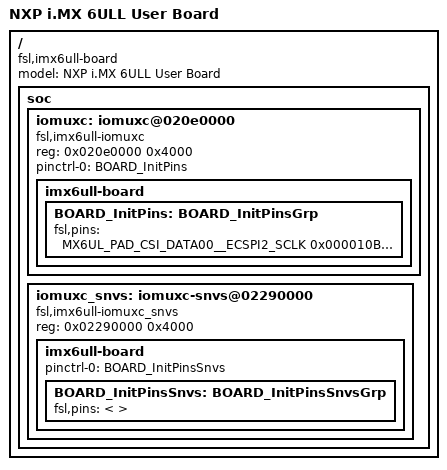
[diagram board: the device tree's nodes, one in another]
/***********************************************************************************************************************
 * This file was generated by the MCUXpresso Config Tools. Any manual edits made to this file
 * will be overwritten if the respective MCUXpresso Config Tools is used to update this file.
 **********************************************************************************************************************/

/*
 * TEXT BELOW IS USED AS SETTING FOR TOOLS *************************************
!!GlobalInfo
product: Pins v11.0
processor: MCIMX6Y2xxx05
package_id: MCIMX6Y2DVM05
mcu_data: i_mx_2_0
processor_version: 11.0.0
 * BE CAREFUL MODIFYING THIS COMMENT - IT IS YAML SETTINGS FOR TOOLS ***********
 */

/*
 * TEXT BELOW IS USED AS SETTING FOR TOOLS *************************************
BOARD_InitPins:
- options: {callFromInitBoot: 'false', coreID: ca7}
- pin_list:
  - {pin_num: B3, peripheral: uSDHC1, signal: 'usdhc_data, 0', pin_signal: SD1_DATA0}
  - {pin_num: B2, peripheral: uSDHC1, signal: 'usdhc_data, 1', pin_signal: SD1_DATA1}
  - {pin_num: A2, peripheral: uSDHC1, signal: 'usdhc_data, 3', pin_signal: SD1_DATA3}
  - {pin_num: B1, peripheral: uSDHC1, signal: 'usdhc_data, 2', pin_signal: SD1_DATA2}
  - {pin_num: C2, peripheral: uSDHC1, signal: usdhc_cmd, pin_signal: SD1_CMD}
  - {pin_num: C1, peripheral: uSDHC1, signal: usdhc_clk, pin_signal: SD1_CLK}
  - {pin_num: L14, peripheral: I2C1, signal: i2c_scl, pin_signal: GPIO1_IO02}
  - {pin_num: L17, peripheral: I2C1, signal: i2c_sda, pin_signal: GPIO1_IO03}
  - {pin_num: K13, peripheral: I2C2, signal: i2c_scl, pin_signal: GPIO1_IO00}
  - {pin_num: L15, peripheral: I2C2, signal: i2c_sda, pin_signal: GPIO1_IO01}
  - {pin_num: A9, peripheral: I2C3, signal: i2c_scl, pin_signal: LCD_DATA01}
  - {pin_num: B9, peripheral: I2C3, signal: i2c_sda, pin_signal: LCD_DATA00}
  - {pin_num: D10, peripheral: I2C4, signal: i2c_scl, pin_signal: LCD_DATA03}
  - {pin_num: E10, peripheral: I2C4, signal: i2c_sda, pin_signal: LCD_DATA02}
  - {pin_num: F5, peripheral: UART6, signal: uart_rx, pin_signal: CSI_MCLK}
  - {pin_num: E5, peripheral: UART6, signal: uart_tx, pin_signal: CSI_PIXCLK}
  - {pin_num: C13, peripheral: UART7, signal: uart_rx, pin_signal: LCD_DATA16}
  - {pin_num: B13, peripheral: UART7, signal: uart_tx, pin_signal: LCD_DATA17}
  - {pin_num: C14, peripheral: UART8, signal: uart_rx, pin_signal: LCD_DATA20}
  - {pin_num: B14, peripheral: UART8, signal: uart_tx, pin_signal: LCD_DATA21}
  - {pin_num: G13, peripheral: UART5, signal: uart_rx, pin_signal: UART5_RX_DATA}
  - {pin_num: F17, peripheral: UART5, signal: uart_tx, pin_signal: UART5_TX_DATA}
  - {pin_num: G16, peripheral: UART4, signal: uart_rx, pin_signal: UART4_RX_DATA}
  - {pin_num: G17, peripheral: UART4, signal: uart_tx, pin_signal: UART4_TX_DATA}
  - {pin_num: H17, peripheral: UART3, signal: uart_tx, pin_signal: UART3_TX_DATA}
  - {pin_num: H16, peripheral: UART3, signal: uart_rx, pin_signal: UART3_RX_DATA}
  - {pin_num: J17, peripheral: UART2, signal: uart_tx, pin_signal: UART2_TX_DATA}
  - {pin_num: J16, peripheral: UART2, signal: uart_rx, pin_signal: UART2_RX_DATA}
  - {pin_num: K16, peripheral: UART1, signal: uart_rx, pin_signal: UART1_RX_DATA}
  - {pin_num: K14, peripheral: UART1, signal: uart_tx, pin_signal: UART1_TX_DATA}
  - {pin_num: D3, peripheral: uSDHC1, signal: usdhc_cd_b, pin_signal: CSI_DATA05}
  - {pin_num: E1, peripheral: ECSPI2, signal: ecspi_miso, pin_signal: CSI_DATA03}
  - {pin_num: E2, peripheral: ECSPI2, signal: ecspi_mosi, pin_signal: CSI_DATA02}
  - {pin_num: E4, peripheral: ECSPI2, signal: ecspi_sclk, pin_signal: CSI_DATA00}
  - {pin_num: E3, peripheral: ECSPI2, signal: 'ecspi_ss, 0', pin_signal: CSI_DATA01}
  - {pin_num: B16, peripheral: ECSPI1, signal: ecspi_miso, pin_signal: LCD_DATA23}
  - {pin_num: A14, peripheral: ECSPI1, signal: ecspi_mosi, pin_signal: LCD_DATA22}
  - {pin_num: C14, peripheral: ECSPI1, signal: ecspi_sclk, pin_signal: LCD_DATA20}
 * BE CAREFUL MODIFYING THIS COMMENT - IT IS YAML SETTINGS FOR TOOLS ***********
 */

/dts-v1/;

#include "skeleton.dtsi"
#include "imx6ull-pinfunc.h"
#include "imx6ull-pinfunc-snvs.h"

/ {
    model = "NXP i.MX 6ULL User Board";
    compatible = "fsl,imx6ull-board", "fsl,imx6ull";

    soc {
        #address-cells = <1>;
        #size-cells = <1>;

        iomuxc: iomuxc@020e0000 {
            compatible = "fsl,imx6ull-iomuxc";
            reg = <0x020e0000 0x4000>;
        };

        iomuxc_snvs: iomuxc-snvs@02290000 {
            compatible = "fsl,imx6ull-iomuxc_snvs";
            reg = <0x02290000 0x4000>;
        };
    };
};

&iomuxc {
    pinctrl-names = "default";
    pinctrl-0 = <&BOARD_InitPins>;
    imx6ull-board {
        BOARD_InitPins: BOARD_InitPinsGrp {                /*!< Function assigned for the core: Cortex-A7[ca7] */
            fsl,pins = <
                MX6UL_PAD_CSI_DATA00__ECSPI2_SCLK          0x000010B0
                MX6UL_PAD_CSI_DATA01__ECSPI2_SS0           0x000010B0
                MX6UL_PAD_CSI_DATA02__ECSPI2_MOSI          0x000010B0
                MX6UL_PAD_CSI_DATA03__ECSPI2_MISO          0x000010B0
                MX6UL_PAD_CSI_DATA05__USDHC1_CD_B          0x000010B0
                MX6UL_PAD_CSI_MCLK__UART6_DCE_TX           0x000010B0
                MX6UL_PAD_CSI_PIXCLK__UART6_DCE_RX         0x000010B0
                MX6UL_PAD_GPIO1_IO00__I2C2_SCL             0x000010B0
                MX6UL_PAD_GPIO1_IO01__I2C2_SDA             0x000010B0
                MX6UL_PAD_GPIO1_IO02__I2C1_SCL             0x000010B0
                MX6UL_PAD_GPIO1_IO03__I2C1_SDA             0x000010B0
                MX6UL_PAD_LCD_DATA00__I2C3_SDA             0x000010B0
                MX6UL_PAD_LCD_DATA01__I2C3_SCL             0x000010B0
                MX6UL_PAD_LCD_DATA02__I2C4_SDA             0x000010B0
                MX6UL_PAD_LCD_DATA03__I2C4_SCL             0x000010B0
                MX6UL_PAD_LCD_DATA16__UART7_DCE_TX         0x000010B0
                MX6UL_PAD_LCD_DATA17__UART7_DCE_RX         0x000010B0
                MX6UL_PAD_LCD_DATA21__UART8_DCE_RX         0x000010B0
                MX6UL_PAD_LCD_DATA22__ECSPI1_MOSI          0x000010B0
                MX6UL_PAD_LCD_DATA23__ECSPI1_MISO          0x000010B0
                MX6UL_PAD_SD1_CLK__USDHC1_CLK              0x000010B0
                MX6UL_PAD_SD1_CMD__USDHC1_CMD              0x000010B0
                MX6UL_PAD_SD1_DATA0__USDHC1_DATA0          0x000010B0
                MX6UL_PAD_SD1_DATA1__USDHC1_DATA1          0x000010B0
                MX6UL_PAD_SD1_DATA2__USDHC1_DATA2          0x000010B0
                MX6UL_PAD_SD1_DATA3__USDHC1_DATA3          0x000010B0
                MX6UL_PAD_UART1_RX_DATA__UART1_DCE_RX      0x000010B0
                MX6UL_PAD_UART1_TX_DATA__UART1_DCE_TX      0x000010B0
                MX6UL_PAD_UART2_RX_DATA__UART2_DCE_RX      0x000010B0
                MX6UL_PAD_UART2_TX_DATA__UART2_DCE_TX      0x000010B0
                MX6UL_PAD_UART3_RX_DATA__UART3_DCE_RX      0x000010B0
                MX6UL_PAD_UART3_TX_DATA__UART3_DCE_TX      0x000010B0
                MX6UL_PAD_UART4_RX_DATA__UART4_DCE_RX      0x000010B0
                MX6UL_PAD_UART4_TX_DATA__UART4_DCE_TX      0x000010B0
                MX6UL_PAD_UART5_RX_DATA__UART5_DCE_RX      0x000010B0
                MX6UL_PAD_UART5_TX_DATA__UART5_DCE_TX      0x000010B0
            >;
        };
    };
};

&iomuxc_snvs {
    pinctrl-names = "default_snvs";
    imx6ull-board {
    pinctrl-0 = <&BOARD_InitPinsSnvs>;
        BOARD_InitPinsSnvs: BOARD_InitPinsSnvsGrp {        /*!< Function assigned for the core: Cortex-A7[ca7] */
            fsl,pins = <
            >;
        };
    };
};

